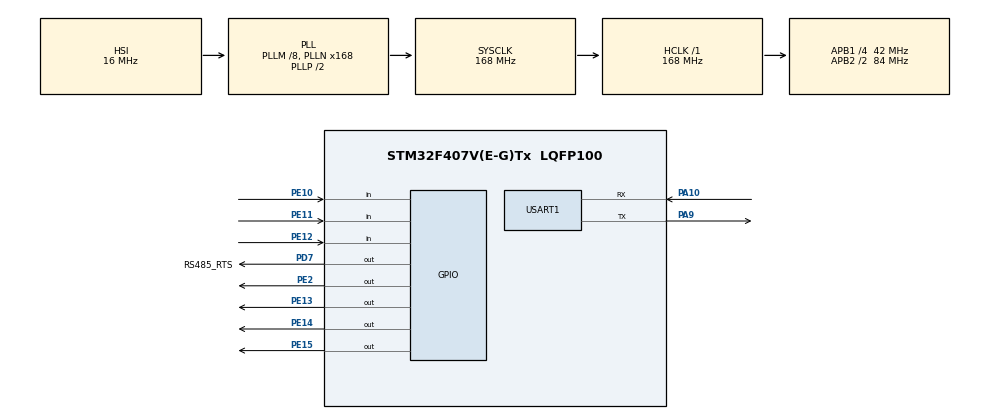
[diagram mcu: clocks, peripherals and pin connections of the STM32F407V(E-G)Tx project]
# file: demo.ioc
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Dma.Request0=USART1_RX
Dma.Request1=USART1_TX
Dma.USART1_RX.0.Direction=DMA_PERIPH_TO_MEMORY
Dma.USART1_RX.0.FIFOMode=DMA_FIFOMODE_DISABLE
Dma.USART1_RX.0.Instance=DMA2_Stream2
Dma.USART1_RX.0.MemDataAlignment=DMA_MDATAALIGN_BYTE
Dma.USART1_RX.0.MemInc=DMA_MINC_ENABLE
Dma.USART1_RX.0.Mode=DMA_CIRCULAR
Dma.USART1_RX.0.PeriphDataAlignment=DMA_PDATAALIGN_BYTE
Dma.USART1_RX.0.PeriphInc=DMA_PINC_DISABLE
Dma.USART1_RX.0.Priority=DMA_PRIORITY_LOW
Dma.USART1_TX.1.Direction=DMA_MEMORY_TO_PERIPH
Dma.USART1_TX.1.FIFOMode=DMA_FIFOMODE_DISABLE
Dma.USART1_TX.1.Instance=DMA2_Stream7
Dma.USART1_TX.1.MemDataAlignment=DMA_MDATAALIGN_BYTE
Dma.USART1_TX.1.MemInc=DMA_MINC_ENABLE
Dma.USART1_TX.1.Mode=DMA_NORMAL
Dma.USART1_TX.1.PeriphDataAlignment=DMA_PDATAALIGN_BYTE
Dma.USART1_TX.1.PeriphInc=DMA_PINC_DISABLE
Dma.USART1_TX.1.Priority=DMA_PRIORITY_LOW
Mcu.Family=STM32F4
Mcu.Name=STM32F407V(E-G)Tx
Mcu.Package=LQFP100
NVIC.DMA2_Stream2_IRQn=true\:0\:0\:false\:false\:true\:false\:true\:true
NVIC.DMA2_Stream7_IRQn=true\:0\:0\:false\:false\:true\:false\:true\:true
NVIC.PriorityGroup=NVIC_PRIORITYGROUP_4
NVIC.USART1_IRQn=true\:0\:0\:false\:false\:true\:true\:true\:true
PA10.Mode=Asynchronous
PA10.Signal=USART1_RX
PA13.Mode=Serial_Wire
PA13.Signal=SYS_JTMS-SWDIO
PA14.Mode=Serial_Wire
PA14.Signal=SYS_JTCK-SWCLK
PA9.Mode=Asynchronous
PA9.Signal=USART1_TX
PB8.GPIO_Pu=GPIO_PULLUP
PB8.Signal=I2C1_SCL
PB9.GPIO_Pu=GPIO_PULLUP
PB9.Signal=I2C1_SDA
PD5.Signal=USART2_TX
PD6.Signal=USART2_RX
PD7.GPIO_Label=RS485_RTS
PD7.GPIO_Speed=GPIO_SPEED_FREQ_HIGH
PD7.PinState=GPIO_PIN_SET
PD7.Signal=GPIO_Output
PE10.Signal=GPIO_Input
PE11.Signal=GPIO_Input
PE12.Signal=GPIO_Input
PE13.Signal=GPIO_Output
PE14.Signal=GPIO_Output
PE15.Signal=GPIO_Output
PE2.Signal=GPIO_Output
PH0-OSC_IN.Mode=HSE-External-Oscillator
PH0-OSC_IN.Signal=RCC_OSC_IN
PH1-OSC_OUT.Mode=HSE-External-Oscillator
PH1-OSC_OUT.Signal=RCC_OSC_OUT
ProjectManager.HeapSize=0x2000
ProjectManager.StackSize=0x2000
ProjectManager.TargetToolchain=MDK-ARM V5
RCC.48MHZClocksFreq_Value=84000000
RCC.AHBFreq_Value=168000000
RCC.APB1CLKDivider=RCC_HCLK_DIV4
RCC.APB1Freq_Value=42000000
RCC.APB1TimFreq_Value=84000000
RCC.APB2CLKDivider=RCC_HCLK_DIV2
RCC.APB2Freq_Value=84000000
RCC.APB2TimFreq_Value=168000000
RCC.CortexFreq_Value=168000000
RCC.HCLKFreq_Value=168000000
RCC.HSE_VALUE=25000000
RCC.HSI_VALUE=16000000
RCC.LSE_VALUE=32768
RCC.PLLM=8
RCC.PLLN=168
RCC.SYSCLKFreq_VALUE=168000000
RCC.SYSCLKSource=RCC_SYSCLKSOURCE_PLLCLK
RCC.VCOOutputFreq_Value=336000000
USART1.VirtualMode=VM_ASYNC
board=custom

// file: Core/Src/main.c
/* USER CODE BEGIN Header */
/**
 ******************************************************************************
 * @file           : main.c
 * @brief          : Main program body
 ******************************************************************************
 * @attention
 *
 * Copyright (c) 2023 STMicroelectronics.
 * All rights reserved.
 *
 * This software is licensed under terms that can be found in the LICENSE file
 * in the root directory of this software component.
 * If no LICENSE file comes with this software, it is provided AS-IS.
 *
 ******************************************************************************
 */
/* USER CODE END Header */
#include "main.h"

UART_HandleTypeDef huart1;
DMA_HandleTypeDef hdma_usart1_rx;
DMA_HandleTypeDef hdma_usart1_tx;

void SystemClock_Config(void);
static void MX_GPIO_Init(void);
static void MX_DMA_Init(void);
static void MX_USART1_UART_Init(void);

int main(void)
{

  /* MCU Configuration--------------------------------------------------------*/

  /* Reset of all peripherals, Initializes the Flash interface and the Systick. */
  HAL_Init();

  /* Configure the system clock */
  SystemClock_Config();

  /* USER CODE BEGIN SysInit */
    __HAL_RCC_GPIOA_CLK_ENABLE();
    __HAL_RCC_GPIOB_CLK_ENABLE();
    __HAL_RCC_GPIOC_CLK_ENABLE();
    __HAL_RCC_GPIOD_CLK_ENABLE();
    __HAL_RCC_GPIOE_CLK_ENABLE();
  /* USER CODE END SysInit */

  /* Initialize all configured peripherals */
  MX_GPIO_Init();
  MX_DMA_Init();
  MX_USART1_UART_Init();
  /* USER CODE BEGIN 2 */
    GuiLite_Test();
  /* USER CODE END 2 */

  /* Infinite loop */
    while (1)
    {

    }
}

void SystemClock_Config(void)
{
  RCC_OscInitTypeDef RCC_OscInitStruct = {0};
  RCC_ClkInitTypeDef RCC_ClkInitStruct = {0};

  /** Configure the main internal regulator output voltage
  */
  __HAL_RCC_PWR_CLK_ENABLE();
  __HAL_PWR_VOLTAGESCALING_CONFIG(PWR_REGULATOR_VOLTAGE_SCALE1);

  /** Initializes the RCC Oscillators according to the specified parameters
  * in the RCC_OscInitTypeDef structure.
  */
  RCC_OscInitStruct.OscillatorType = RCC_OSCILLATORTYPE_HSI;
  RCC_OscInitStruct.HSIState = RCC_HSI_ON;
  RCC_OscInitStruct.HSICalibrationValue = RCC_HSICALIBRATION_DEFAULT;
  RCC_OscInitStruct.PLL.PLLState = RCC_PLL_ON;
  RCC_OscInitStruct.PLL.PLLSource = RCC_PLLSOURCE_HSI;
  RCC_OscInitStruct.PLL.PLLM = 8;
  RCC_OscInitStruct.PLL.PLLN = 168;
  RCC_OscInitStruct.PLL.PLLP = RCC_PLLP_DIV2;
  RCC_OscInitStruct.PLL.PLLQ = 4;
  if (HAL_RCC_OscConfig(&RCC_OscInitStruct) != HAL_OK)
  {
    Error_Handler();
  }

  /** Initializes the CPU, AHB and APB buses clocks
  */
  RCC_ClkInitStruct.ClockType = RCC_CLOCKTYPE_HCLK|RCC_CLOCKTYPE_SYSCLK
                              |RCC_CLOCKTYPE_PCLK1|RCC_CLOCKTYPE_PCLK2;
  RCC_ClkInitStruct.SYSCLKSource = RCC_SYSCLKSOURCE_PLLCLK;
  RCC_ClkInitStruct.AHBCLKDivider = RCC_SYSCLK_DIV1;
  RCC_ClkInitStruct.APB1CLKDivider = RCC_HCLK_DIV4;
  RCC_ClkInitStruct.APB2CLKDivider = RCC_HCLK_DIV2;

  if (HAL_RCC_ClockConfig(&RCC_ClkInitStruct, FLASH_LATENCY_5) != HAL_OK)
  {
    Error_Handler();
  }
}

static void MX_USART1_UART_Init(void)
{

  huart1.Instance = USART1;
  huart1.Init.BaudRate = 115200;
  huart1.Init.WordLength = UART_WORDLENGTH_8B;
  huart1.Init.StopBits = UART_STOPBITS_1;
  huart1.Init.Parity = UART_PARITY_NONE;
  huart1.Init.Mode = UART_MODE_TX_RX;
  huart1.Init.HwFlowCtl = UART_HWCONTROL_NONE;
  huart1.Init.OverSampling = UART_OVERSAMPLING_16;
  if (HAL_UART_Init(&huart1) != HAL_OK)
  {
    Error_Handler();
  }

}

static void MX_DMA_Init(void)
{

  /* DMA controller clock enable */
  __HAL_RCC_DMA2_CLK_ENABLE();

  /* DMA interrupt init */
  /* DMA2_Stream2_IRQn interrupt configuration */
  HAL_NVIC_SetPriority(DMA2_Stream2_IRQn, 0, 0);
  HAL_NVIC_EnableIRQ(DMA2_Stream2_IRQn);
  /* DMA2_Stream7_IRQn interrupt configuration */
  HAL_NVIC_SetPriority(DMA2_Stream7_IRQn, 0, 0);
  HAL_NVIC_EnableIRQ(DMA2_Stream7_IRQn);

}

static void MX_GPIO_Init(void)
{
  GPIO_InitTypeDef GPIO_InitStruct = {0};

  /* GPIO Ports Clock Enable */
  __HAL_RCC_GPIOE_CLK_ENABLE();
  __HAL_RCC_GPIOH_CLK_ENABLE();
  __HAL_RCC_GPIOA_CLK_ENABLE();
  __HAL_RCC_GPIOD_CLK_ENABLE();
  __HAL_RCC_GPIOB_CLK_ENABLE();

  /*Configure GPIO pin Output Level */
  HAL_GPIO_WritePin(GPIOE, GPIO_PIN_2|GPIO_PIN_13|GPIO_PIN_14|GPIO_PIN_15, GPIO_PIN_RESET);

  /*Configure GPIO pin Output Level */
  HAL_GPIO_WritePin(RS485_RTS_GPIO_Port, RS485_RTS_Pin, GPIO_PIN_SET);

  /*Configure GPIO pins : PE2 PE13 PE14 PE15 */
  GPIO_InitStruct.Pin = GPIO_PIN_2|GPIO_PIN_13|GPIO_PIN_14|GPIO_PIN_15;
  GPIO_InitStruct.Mode = GPIO_MODE_OUTPUT_PP;
  GPIO_InitStruct.Pull = GPIO_NOPULL;
  GPIO_InitStruct.Speed = GPIO_SPEED_FREQ_LOW;
  HAL_GPIO_Init(GPIOE, &GPIO_InitStruct);

  /*Configure GPIO pins : PE10 PE11 PE12 */
  GPIO_InitStruct.Pin = GPIO_PIN_10|GPIO_PIN_11|GPIO_PIN_12;
  GPIO_InitStruct.Mode = GPIO_MODE_INPUT;
  GPIO_InitStruct.Pull = GPIO_NOPULL;
  HAL_GPIO_Init(GPIOE, &GPIO_InitStruct);

  /*Configure GPIO pins : PD5 PD6 */
  GPIO_InitStruct.Pin = GPIO_PIN_5|GPIO_PIN_6;
  GPIO_InitStruct.Mode = GPIO_MODE_AF_PP;
  GPIO_InitStruct.Pull = GPIO_NOPULL;
  GPIO_InitStruct.Speed = GPIO_SPEED_FREQ_VERY_HIGH;
  GPIO_InitStruct.Alternate = GPIO_AF7_USART2;
  HAL_GPIO_Init(GPIOD, &GPIO_InitStruct);

  /*Configure GPIO pin : RS485_RTS_Pin */
  GPIO_InitStruct.Pin = RS485_RTS_Pin;
  GPIO_InitStruct.Mode = GPIO_MODE_OUTPUT_PP;
  GPIO_InitStruct.Pull = GPIO_NOPULL;
  GPIO_InitStruct.Speed = GPIO_SPEED_FREQ_HIGH;
  HAL_GPIO_Init(RS485_RTS_GPIO_Port, &GPIO_InitStruct);

  /*Configure GPIO pins : PB8 PB9 */
  GPIO_InitStruct.Pin = GPIO_PIN_8|GPIO_PIN_9;
  GPIO_InitStruct.Mode = GPIO_MODE_AF_OD;
  GPIO_InitStruct.Pull = GPIO_PULLUP;
  GPIO_InitStruct.Speed = GPIO_SPEED_FREQ_VERY_HIGH;
  GPIO_InitStruct.Alternate = GPIO_AF4_I2C1;
  HAL_GPIO_Init(GPIOB, &GPIO_InitStruct);

}

void Error_Handler(void)
{
    __disable_irq();
    while (1)
    {
    }
}

#ifdef  USE_FULL_ASSERT
/**
  * @brief  Reports the name of the source file and the source line number
  *         where the assert_param error has occurred.
  * @param  file: pointer to the source file name
  * @param  line: assert_param error line source number
  * @retval None
  */
void assert_failed(uint8_t *file, uint32_t line)
{
  /* USER CODE BEGIN 6 */
    /* User can add his own implementation to report the file name and line number,
       ex: PRINTF("Wrong parameters value: file %s on line %d\r\n", file, line) */
  /* USER CODE END 6 */
}
#endif /* USE_FULL_ASSERT */
